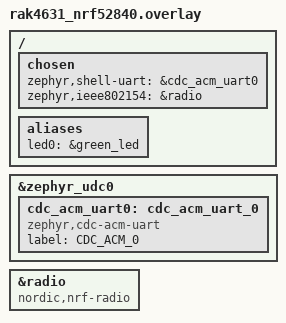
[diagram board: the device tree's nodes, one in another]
/*
 * Definitive Devicetree Overlay for RAK4631 OpenThread Application
 */
/ {
    chosen {
        /*
         * FIX #1: Tell Zephyr's shell and logging system to use the
         * virtual COM port we are about to create over USB.
         */
        zephyr,shell-uart = &cdc_acm_uart0;

        /*
         * FIX #2: Tell Zephyr's 802.15.4 subsystem to use the
         * nRF52840's built-in radio peripheral.
         */
        zephyr,ieee802154 = &radio;
    };

    aliases {
        /* This confirms our app's 'led0' will use the RAK's green LED */
        led0 = &green_led;
    };
};

/*
 * FIX #3: Find the main USB device controller and create a virtual
 * COM port (CDC-ACM) instance inside it. Crucially, we set its
 * status to "okay" to actually enable it.
 */
&zephyr_udc0 {
    cdc_acm_uart0: cdc_acm_uart_0 {
        compatible = "zephyr,cdc-acm-uart";
        label = "CDC_ACM_0";
        status = "okay";
    };
};

/*
 * FIX #4: Find the radio peripheral, set its status to "okay",
 * and add the compatible string that the Kconfig dependency check
 * is explicitly looking for.
 */
&radio {
    compatible = "nordic,nrf-radio", "nordic,nrf-ieee802154";
    status = "okay";
};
